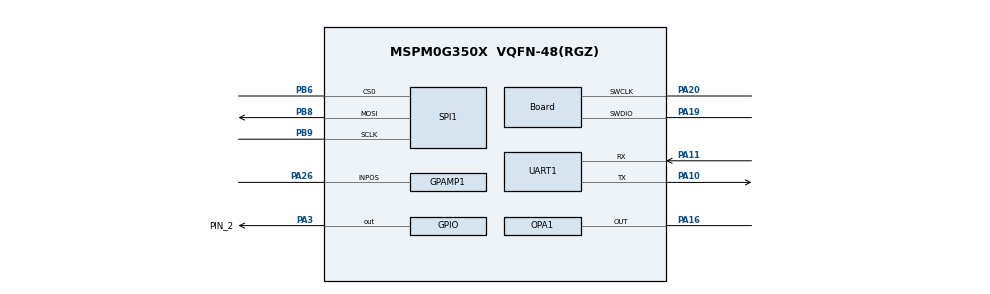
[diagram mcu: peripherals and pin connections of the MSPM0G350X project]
/**
 * @cliArgs --device "MSPM0G350X" --package "VQFN-48(RGZ)" --part "Default" --product "mspm0_sdk@1.20.01.06"
 * @versions {"tool":"1.18.1+3343"}
 */

/**
 * Import the modules used in this configuration.
 */
const ADC12         = scripting.addModule("/ti/driverlib/ADC12", {}, false);
const ADC121        = ADC12.addInstance();
const Board         = scripting.addModule("/ti/driverlib/Board");
const COMP          = scripting.addModule("/ti/driverlib/COMP", {}, false);
const COMP1         = COMP.addInstance();
const GPAMP         = scripting.addModule("/ti/driverlib/GPAMP", {}, false);
const GPAMP1        = GPAMP.addInstance();
const GPIO          = scripting.addModule("/ti/driverlib/GPIO", {}, false);
const GPIO1         = GPIO.addInstance();
const GPIO2         = GPIO.addInstance();
const OPA           = scripting.addModule("/ti/driverlib/OPA", {}, false);
const OPA1          = OPA.addInstance();
const SPI           = scripting.addModule("/ti/driverlib/SPI", {}, false);
const SPI1          = SPI.addInstance();
const SYSCTL        = scripting.addModule("/ti/driverlib/SYSCTL");
const TIMER         = scripting.addModule("/ti/driverlib/TIMER", {}, false);
const TIMER1        = TIMER.addInstance();
const UART          = scripting.addModule("/ti/driverlib/UART", {}, false);
const UART1         = UART.addInstance();
const ProjectConfig = scripting.addModule("/ti/project_config/ProjectConfig");

/**
 * Write custom configuration values to the imported modules.
 */
const divider4       = system.clockTree["PLL_CLK0_DIV"];
divider4.divideValue = 4;

const divider7       = system.clockTree["PLL_PDIV"];
divider7.divideValue = 8;

const gate7  = system.clockTree["MFCLKGATE"];
gate7.enable = true;

const gate8  = system.clockTree["MFPCLKGATE"];
gate8.enable = true;

const multiplier2         = system.clockTree["PLL_QDIV"];
multiplier2.multiplyValue = 40;

const pinFunction4     = system.clockTree["HFXT"];
pinFunction4.inputFreq = 8;

ADC121.$name                       = "ADC12_0";
ADC121.repeatMode                  = true;
ADC121.sampClkDiv                  = "DL_ADC12_CLOCK_DIVIDE_8";
ADC121.samplingOperationMode       = "sequence";
ADC121.endAdd                      = 1;
ADC121.adcMem1chansel              = "DL_ADC12_INPUT_CHAN_12";
ADC121.enabledInterrupts           = ["DL_ADC12_INTERRUPT_MEM0_RESULT_LOADED","DL_ADC12_INTERRUPT_MEM1_RESULT_LOADED"];
ADC121.sampClkSrc                  = "DL_ADC12_CLOCK_ULPCLK";
ADC121.peripheral.adcPin12.$assign = "PA14";
ADC121.adcPin0Config.$name         = "ti_driverlib_gpio_GPIOPinGeneric0";
ADC121.adcPin12Config.$name        = "ti_driverlib_gpio_GPIOPinGeneric8";

Board.peripheral.$assign          = "DEBUGSS";
Board.peripheral.swclkPin.$assign = "PA20";
Board.peripheral.swdioPin.$assign = "PA19";

COMP1.$name                  = "COMP_0";
COMP1.vSource                = "DL_COMP_REF_SOURCE_VDDA_DAC";
COMP1.hysteresis             = "DL_COMP_HYSTERESIS_20";
COMP1.terminalSelect         = "DL_COMP_REF_TERMINAL_SELECT_NEG";
COMP1.controlSelect          = "DL_COMP_DAC_CONTROL_SW";
COMP1.setDACCode0            = 0x4D;
COMP1.outputEnable           = true;
COMP1.peripheral.$assign     = "COMP0";
COMP1.compPinOutConfig.$name = "ti_driverlib_gpio_GPIOPinGeneric10";

GPAMP1.$name                       = "GPAMP_0";
GPAMP1.cfgPSELChannel              = "IN_POS";
GPAMP1.cfgNSELChannel              = "IN_NEG";
GPAMP1.cfgChoppingMode             = "STANDARD";
GPAMP1.peripheral.InPosPin.$assign = "PA26";
GPAMP1.InPosPinConfig.$name        = "ti_driverlib_gpio_GPIOPinGeneric1";
GPAMP1.InNegPinConfig.$name        = "ti_driverlib_gpio_GPIOPinGeneric9";

GPIO1.$name                                       = "OLED";
GPIO1.associatedPins[0].$name                     = "DC";
GPIO1.associatedPins[0].assignedPin               = "7";
GPIO1.associatedPins[0].pin.$assignAllowConflicts = "PB7";

GPIO2.$name                         = "A";
GPIO2.associatedPins[0].$name       = "PIN_2";
GPIO2.associatedPins[0].pin.$assign = "PA3";

OPA1.$name                     = "OPA_1";
OPA1.profile                   = "CONFIG_PROFILE_3";
OPA1.peripheral.$assign        = "OPA1";
OPA1.peripheral.OutPin.$assign = "PA16";
OPA1.OutPinConfig.$name        = "ti_driverlib_gpio_GPIOPinGeneric11";

SPI1.$name                          = "SPI_0";
SPI1.peripheral.$assign             = "SPI1";
SPI1.peripheral.sclkPin.$assign     = "PB9";
SPI1.peripheral.mosiPin.$assign     = "PB8";
SPI1.peripheral.cs0Pin.$assign      = "PB6";
SPI1.sclkPinConfig.$name            = "ti_driverlib_gpio_GPIOPinGeneric2";
SPI1.mosiPinConfig.$name            = "ti_driverlib_gpio_GPIOPinGeneric3";
SPI1.misoPinConfig.$name            = "ti_driverlib_gpio_GPIOPinGeneric4";
SPI1.misoPinConfig.internalResistor = "PULL_DOWN";
SPI1.cs0PinConfig.$name             = "ti_driverlib_gpio_GPIOPinGeneric5";

SYSCTL.MFCLKEn     = true;
SYSCTL.MFPCLKEn    = true;
SYSCTL.clockTreeEn = true;

TIMER1.$name              = "TIMER_0";
TIMER1.timerClkPrescale   = 256;
TIMER1.timerMode          = "PERIODIC";
TIMER1.timerStartTimer    = true;
TIMER1.interrupts         = ["ZERO"];
TIMER1.timerPeriod        = "0.1ms";
TIMER1.peripheral.$assign = "TIMA0";

UART1.$name                    = "UART_0";
UART1.enabledInterrupts        = ["RX"];
UART1.uartClkSrc               = "MFCLK";
UART1.targetBaudRate           = 115200;
UART1.peripheral.$assign       = "UART0";
UART1.peripheral.rxPin.$assign = "PA11";
UART1.peripheral.txPin.$assign = "PA10";
UART1.txPinConfig.$name        = "ti_driverlib_gpio_GPIOPinGeneric6";
UART1.rxPinConfig.$name        = "ti_driverlib_gpio_GPIOPinGeneric7";

ProjectConfig.deviceSpin = "MSPM0G3507";
scripting.suppress("Migrating requires going through the Switch Board or Device menu in the Device View section\\.", ProjectConfig, "deviceSpin");

/**
 * Pinmux solution for unlocked pins/peripherals. This ensures that minor changes to the automatic solver in a future
 * version of the tool will not impact the pinmux you originally saw.  These lines can be completely deleted in order to
 * re-solve from scratch.
 */
ADC121.peripheral.$suggestSolution           = "ADC0";
ADC121.peripheral.adcPin0.$suggestSolution   = "PA27";
COMP1.peripheral.compPinOut.$suggestSolution = "PA7";
GPAMP1.peripheral.$suggestSolution           = "GPAMP";
GPAMP1.peripheral.InNegPin.$suggestSolution  = "PA18";
SPI1.peripheral.misoPin.$suggestSolution     = "PB14";
